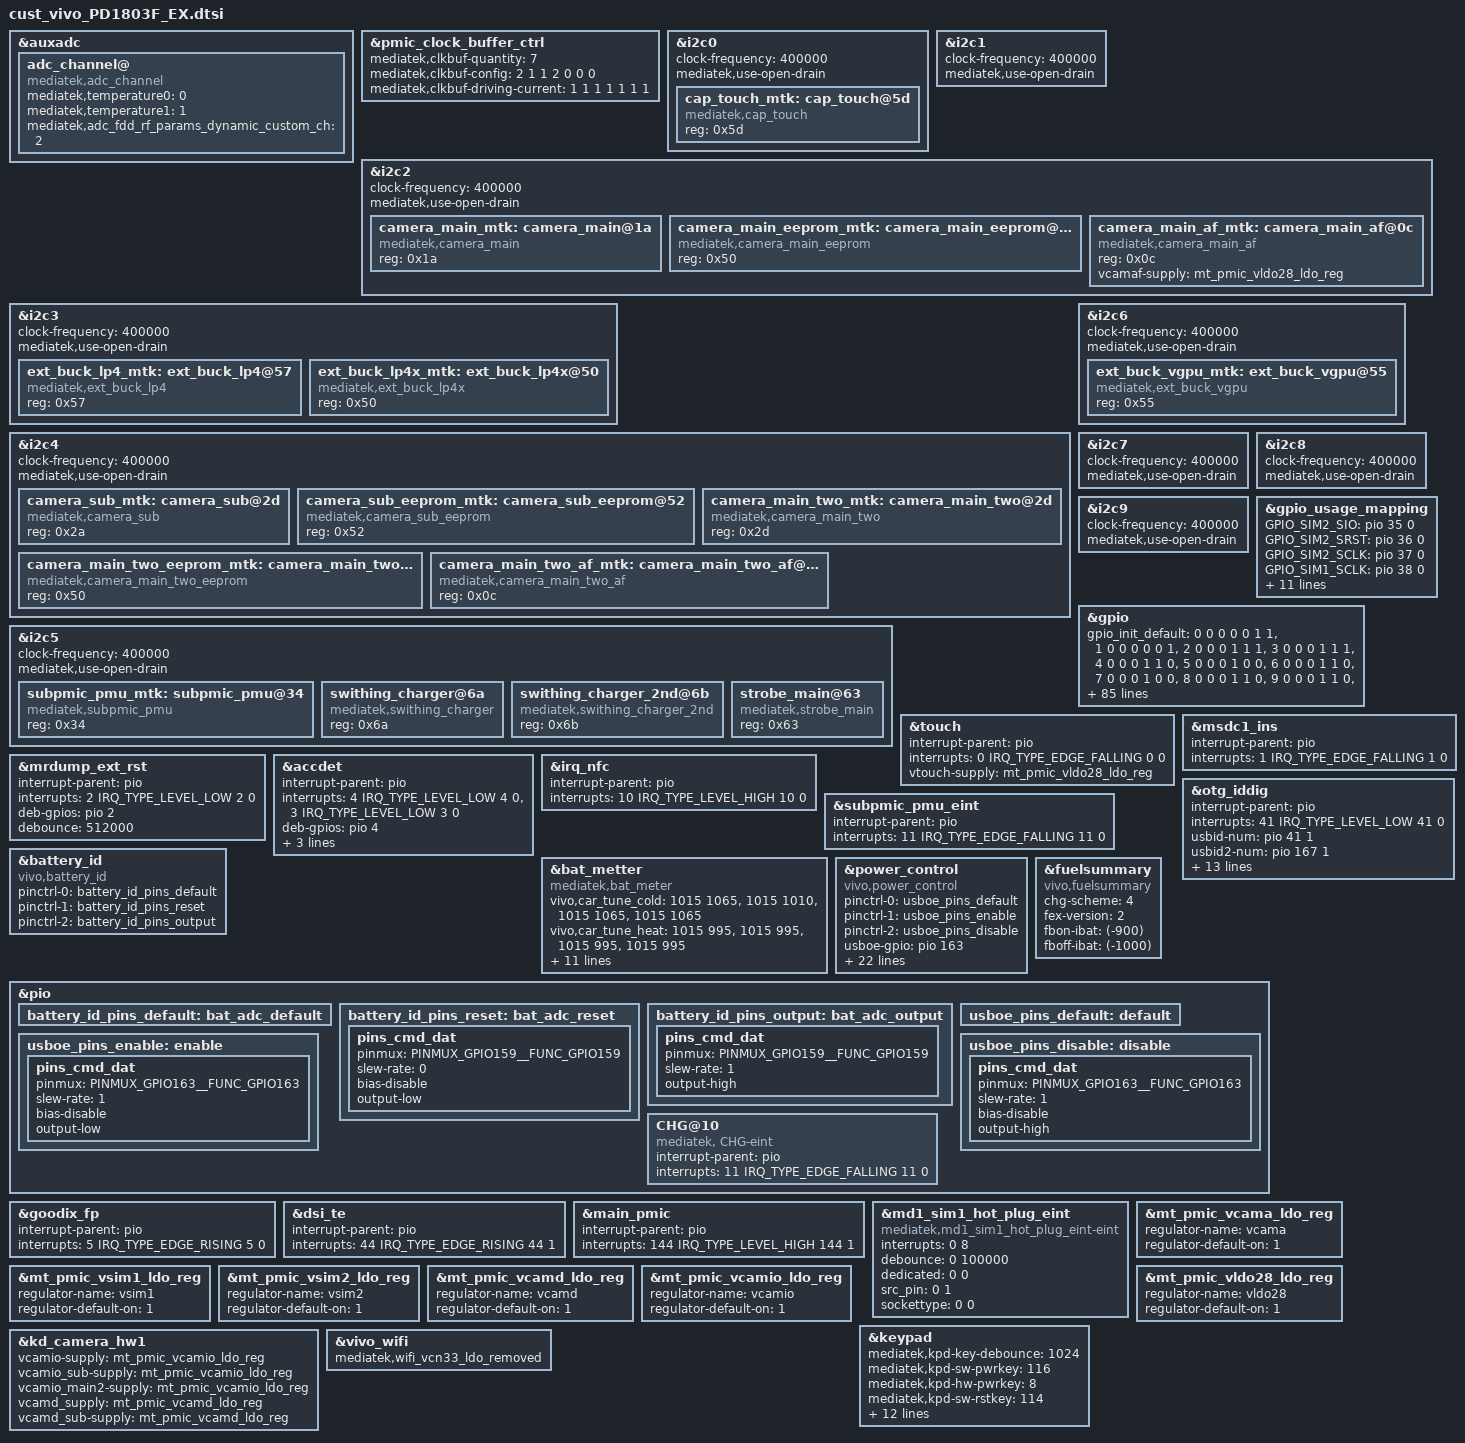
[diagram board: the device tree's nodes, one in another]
/*
 * Generated by MTK SP DrvGen Version: 3.5.160809 for MT6765.
 * 2018-01-30 14:59:45
 * Do Not Modify The File.
 * Copyright Mediatek Inc. (c) 2016.
*/

/*************************
 * ADC DTSI File
*************************/

&auxadc {
	adc_channel@ {
		compatible = "mediatek,adc_channel";
		mediatek,temperature0 = <0>;
		mediatek,temperature1 = <1>;
		mediatek,adc_fdd_rf_params_dynamic_custom_ch = <2>;
		status = "okay";
	};
};


/*************************
 * CLK_BUF DTSI File
*************************/

&pmic_clock_buffer_ctrl {
	mediatek,clkbuf-quantity = <7>;
	mediatek,clkbuf-config = <2 1 1 2 0 0 0>;
	mediatek,clkbuf-driving-current = <1 1 1 1 1 1 1>;
	status = "okay";
};


/*************************
 * I2C DTSI File
*************************/

&i2c0 {
	#address-cells = <1>;
	#size-cells = <0>;
	clock-frequency = <400000>;
	mediatek,use-open-drain;
	cap_touch_mtk:cap_touch@5d {
		compatible = "mediatek,cap_touch";
		reg = <0x5d>;
		status = "okay";
	};

};

&i2c1 {
	#address-cells = <1>;
	#size-cells = <0>;
	clock-frequency = <400000>;
	mediatek,use-open-drain;
};

&i2c2 {
	#address-cells = <1>;
	#size-cells = <0>;
	clock-frequency = <400000>;
	mediatek,use-open-drain;
	camera_main_mtk:camera_main@1a {
		compatible = "mediatek,camera_main";
		reg = <0x1a>;
		status = "okay";
	};

	camera_main_eeprom_mtk:camera_main_eeprom@50 {
		compatible = "mediatek,camera_main_eeprom";
		reg = <0x50>;
		status = "okay";
	};

	camera_main_af_mtk:camera_main_af@0c {
		compatible = "mediatek,camera_main_af";
		reg = <0x0c>;
		status = "okay";
	};

};

&i2c3 {
	#address-cells = <1>;
	#size-cells = <0>;
	clock-frequency = <400000>;
	mediatek,use-open-drain;
	ext_buck_lp4_mtk:ext_buck_lp4@57 {
		compatible = "mediatek,ext_buck_lp4";
		reg = <0x57>;
		status = "okay";
	};

	ext_buck_lp4x_mtk:ext_buck_lp4x@50 {
		compatible = "mediatek,ext_buck_lp4x";
		reg = <0x50>;
		status = "okay";
	};

};

&i2c4 {
	#address-cells = <1>;
	#size-cells = <0>;
	clock-frequency = <400000>;
	mediatek,use-open-drain;
	camera_sub_mtk:camera_sub@2d {
		compatible = "mediatek,camera_sub";
		reg = <0x2a>;
		status = "okay";
	};

	camera_sub_eeprom_mtk:camera_sub_eeprom@52 {
		compatible = "mediatek,camera_sub_eeprom";
		reg = <0x52>;
		status = "okay";
	};
	
	camera_main_two_mtk:camera_main_two@2d {
		compatible = "mediatek,camera_main_two";
		reg = <0x2d>;
		status = "okay";
	};
	
	camera_main_two_eeprom_mtk:camera_main_two_eeprom@50 {
		compatible = "mediatek,camera_main_two_eeprom";
		reg = <0x50>;
		status = "okay";
	};

	camera_main_two_af_mtk:camera_main_two_af@0c {
		compatible = "mediatek,camera_main_two_af";
		reg = <0x0c>;
		status = "okay";
	};



};

&i2c5 {
	#address-cells = <1>;
	#size-cells = <0>;
	clock-frequency = <400000>;
	mediatek,use-open-drain;
	subpmic_pmu_mtk:subpmic_pmu@34 {
		compatible = "mediatek,subpmic_pmu";
		reg = <0x34>;
		status = "okay";
	};

	swithing_charger@6a {
		compatible = "mediatek,swithing_charger";
		reg = <0x6a>;
		status = "okay";
    };
    swithing_charger_2nd@6b {
		compatible = "mediatek,swithing_charger_2nd";
		reg = <0x6b>;
		status = "okay";
    };
    	/*hope add for flashlight i2c device start*/
	strobe_main@63 {
	        compatible = "mediatek,strobe_main";
	        reg = <0x63>;
	        status = "okay";
	};
	/*hope add for flashlight i2c device end*/
};

&i2c6 {
	#address-cells = <1>;
	#size-cells = <0>;
	clock-frequency = <400000>;
	mediatek,use-open-drain;

	ext_buck_vgpu_mtk:ext_buck_vgpu@55 {
		compatible = "mediatek,ext_buck_vgpu";
		reg = <0x55>;
		status = "okay";
	};

};

&i2c7 {
	#address-cells = <1>;
	#size-cells = <0>;
	clock-frequency = <400000>;
	mediatek,use-open-drain;
};

&i2c8 {
	#address-cells = <1>;
	#size-cells = <0>;
	clock-frequency = <400000>;
	mediatek,use-open-drain;
};

&i2c9 {
	#address-cells = <1>;
	#size-cells = <0>;
	clock-frequency = <400000>;
	mediatek,use-open-drain;
};



/*************************
 * GPIO DTSI File
*************************/

&gpio_usage_mapping {
	GPIO_SIM2_SIO = <&pio 35 0>;
	GPIO_SIM2_SRST = <&pio 36 0>;
	GPIO_SIM2_SCLK = <&pio 37 0>;
	GPIO_SIM1_SCLK = <&pio 38 0>;
	GPIO_SIM1_SRST = <&pio 39 0>;
	GPIO_SIM1_SIO = <&pio 40 0>;
	GPIO_SIM1_HOT_PLUG = <&pio 47 0>;
	GPIO_FDD_BAND_SUPPORT_DETECT_1ST_PIN = <&pio 175 0>;
	GPIO_FDD_BAND_SUPPORT_DETECT_2ND_PIN = <&pio 174 0>;
	GPIO_FDD_BAND_SUPPORT_DETECT_3RD_PIN = <&pio 173 0>;
	GPIO_FDD_BAND_SUPPORT_DETECT_4TH_PIN = <&pio 176 0>;
};

&gpio{
	gpio_init_default = <0 0 0 0 0 1 1>,
		<1 0 0 0 0 0 1>,
		<2 0 0 0 1 1 1>,
		<3 0 0 0 1 1 1>,
		<4 0 0 0 1 1 0>,
		<5 0 0 0 1 0 0>,
		<6 0 0 0 1 1 0>,
		<7 0 0 0 1 0 0>,
		<8 0 0 0 1 1 0>,
		<9 0 0 0 1 1 0>,
		<10 0 0 0 0 1 0>,
		<11 0 0 0 1 1 0>,
		<12 0 0 0 1 0 0>,
		<13 3 0 0 1 0 0>,
		<14 3 1 0 0 0 0>,
		<15 3 1 0 0 0 0>,
		<16 3 1 0 0 0 0>,
		<17 0 0 0 1 0 0>,
		<18 0 0 0 1 0 0>,
		<19 0 0 0 1 0 0>,
		<20 0 0 0 1 0 0>,
		<21 0 0 0 1 0 0>,
		<22 0 0 0 1 0 0>,
		<23 0 0 0 1 0 0>,
		<24 0 0 0 1 0 0>,
		<25 0 0 0 1 0 0>,
		<26 0 0 0 1 0 0>,
		<27 0 0 0 1 0 0>,
		<28 0 0 0 1 0 0>,
		<29 1 1 0 0 0 1>,
		<30 1 0 0 1 1 1>,
		<31 1 0 0 1 1 1>,
		<32 1 0 0 1 1 1>,
		<33 1 0 0 1 1 1>,
		<34 1 0 0 1 1 1>,
		<35 1 0 0 1 1 0>,
		<36 1 1 0 0 0 0>,
		<37 1 1 0 0 0 0>,
		<38 1 1 0 0 0 0>,
		<39 1 1 0 0 0 0>,
		<40 1 0 0 1 1 0>,
		<41 0 0 0 0 0 0>,
		<42 0 0 0 1 0 0>,
		<43 1 1 0 0 0 0>,
		<44 1 0 0 1 0 0>,
		<45 0 1 0 0 0 0>,
		<46 0 0 0 0 0 0>,
		<47 1 0 0 0 0 0>,
		<48 1 0 0 0 0 0>,
		<49 1 0 0 0 0 0>,
		<50 2 0 0 1 1 0>,
		<51 2 1 0 0 0 0>,
		<52 1 1 0 1 0 0>,
		<53 1 1 0 1 0 0>,
		<54 0 0 0 1 0 0>,
		<55 0 0 0 1 0 0>,
		<56 1 1 0 1 0 0>,
		<57 0 0 0 1 0 0>,
		<58 0 0 0 1 0 0>,
		<59 1 0 0 1 0 0>,
		<60 1 0 0 1 0 0>,
		<61 1 0 0 1 0 0>,
		<62 1 0 0 1 0 0>,
		<63 1 0 0 1 0 0>,
		<64 1 0 0 1 0 0>,
		<65 1 0 0 1 0 0>,
		<66 1 0 0 1 0 0>,
		<67 1 0 0 1 0 0>,
		<68 1 0 0 1 0 0>,
		<69 1 1 0 1 0 0>,
		<70 1 1 0 1 0 0>,
		<71 0 0 0 1 0 0>,
		<72 1 1 0 1 0 0>,
		<73 0 1 0 1 0 0>,
		<74 0 1 0 1 0 0>,
		<75 0 0 0 1 0 0>,
		<76 1 1 0 1 0 0>,
		<77 1 1 0 1 0 0>,
		<78 1 1 0 1 0 0>,
		<79 0 0 0 1 0 0>,
		<80 0 0 0 1 0 0>,
		<81 1 0 0 0 0 0>,
		<82 1 0 0 0 0 0>,
		<83 1 0 0 0 0 0>,
		<84 1 0 0 0 0 0>,
		<85 1 1 0 1 0 0>,
		<86 1 1 0 1 0 0>,
		<87 0 0 0 1 0 0>,
		<88 0 0 0 1 0 0>,
		<89 0 0 0 1 0 0>,
		<90 0 0 0 1 0 0>,
		<91 0 1 0 1 0 0>,
		<92 0 0 0 1 0 0>,
		<93 1 0 0 1 1 0>,
		<94 0 0 0 1 0 0>,
		<95 1 0 0 1 1 0>,
		<96 1 1 0 0 0 0>,
		<97 0 1 0 0 0 0>,
		<98 0 1 0 0 0 0>,
		<99 1 1 0 0 0 0>,
		<100 1 1 0 0 0 0>,
		<101 0 1 1 0 0 0>,
		<102 0 1 1 0 0 0>,
		<103 1 0 0 0 0 0>,
		<104 1 0 0 0 0 0>,
		<105 1 0 0 0 0 0>,
		<106 1 0 0 0 0 0>,
		<107 0 1 0 0 0 0>,
		<108 1 1 0 0 0 0>,
		<109 0 0 0 1 1 0>,
		<110 0 0 0 1 0 0>,
		<111 0 0 0 1 0 0>,
		<112 0 0 0 1 0 0>,
		<113 0 1 0 0 0 0>,
		<114 0 0 0 1 0 0>,
		<115 0 0 0 1 0 0>,
		<116 0 0 0 1 0 0>,
		<117 0 0 0 1 0 0>,
		<118 0 0 0 1 0 0>,
		<119 0 0 0 1 0 0>,
		<120 0 0 0 1 0 0>,
		<121 0 0 0 0 0 0>,
		<122 1 0 0 1 1 1>,
		<123 1 0 0 1 1 1>,
		<124 1 1 0 0 0 1>,
		<125 1 0 0 1 1 1>,
		<126 1 0 0 1 1 1>,
		<127 1 0 0 1 1 1>,
		<128 1 0 0 1 1 1>,
		<129 1 0 0 1 1 1>,
		<130 1 0 0 1 1 1>,
		<131 1 0 0 1 0 1>,
		<132 1 0 0 1 1 1>,
		<133 1 1 1 0 0 1>,
		<134 1 0 0 1 0 0>,
		<135 1 1 0 0 0 0>,
		<136 1 1 0 0 0 0>,
		<137 1 1 0 0 0 0>,
		<138 1 1 0 0 0 0>,
		<139 1 1 0 0 0 0>,
		<140 1 0 0 1 0 0>,
		<141 1 0 0 1 0 0>,
		<142 1 0 0 1 0 0>,
		<143 1 0 0 1 0 0>,
		<144 1 0 0 1 0 0>,
		<145 1 1 1 0 0 0>,
		<146 1 0 0 1 0 0>,
		<147 1 1 0 0 0 0>,
		<148 1 1 0 0 0 0>,
		<149 1 1 0 0 0 0>,
		<150 0 1 0 1 1 0>,
		<151 0 1 0 0 0 0>,
		<152 0 1 0 0 0 0>,
		<153 0 1 0 0 0 0>,
		<154 0 1 0 0 0 0>,
		<155 0 1 0 1 0 0>,
		<156 0 0 1 0 0 0>,
		<157 1 0 0 1 0 0>,
		<158 1 0 0 1 0 0>,
		<159 0 1 1 0 0 0>,
		<160 0 0 0 1 0 0>,
		<161 1 0 0 0 0 0>,
		<162 1 0 0 0 0 0>,
		<163 0 1 0 0 0 0>,
		<164 0 0 0 0 0 0>,
		<165 0 0 0 0 0 0>,
		<166 0 1 0 1 0 0>,
		<167 0 0 0 1 0 0>,
		<168 0 0 0 1 0 0>,
		<169 0 1 0 0 0 0>,
		<170 0 1 0 0 0 0>,
		<171 0 0 0 1 1 0>,
		<172 0 0 0 1 1 0>,
		<173 0 0 0 1 1 0>,
		<174 0 0 0 1 1 0>,
		<175 0 0 0 1 1 0>,
		<176 0 0 0 1 1 0>,
		<177 0 0 0 1 1 0>,
		<178 0 1 0 0 0 0>,
		<179 0 0 0 1 0 0>;
};


/*************************
 * EINT DTSI File
*************************/

#include <dt-bindings/interrupt-controller/irq.h>
#include <dt-bindings/interrupt-controller/arm-gic.h>

&touch {
	interrupt-parent = <&pio>;
	interrupts = <0 IRQ_TYPE_EDGE_FALLING 0 0>;
	status = "okay";
};

&msdc1_ins {
	interrupt-parent = <&pio>;
	interrupts = <1 IRQ_TYPE_EDGE_FALLING 1 0>;
	status = "okay";
};

&mrdump_ext_rst {
	interrupt-parent = <&pio>;
	interrupts = <2 IRQ_TYPE_LEVEL_LOW 2 0>;
	deb-gpios = <&pio 2 0>;
	debounce = <512000>;
	status = "okay";
};

&accdet {
	interrupt-parent = <&pio>;
	interrupts = <4 IRQ_TYPE_LEVEL_LOW 4 0>,
					<3 IRQ_TYPE_LEVEL_LOW 3 0>;
	deb-gpios = <&pio 4 0>;
	deb-rgpios = <&pio 3 0>;
	debounce = <256000>;
	debounce1 = <256000>;
	status = "okay";
};

&irq_nfc {
	interrupt-parent = <&pio>;
	interrupts = <10 IRQ_TYPE_LEVEL_HIGH 10 0>;
	status = "okay";
};

&subpmic_pmu_eint {
	interrupt-parent = <&pio>;
	interrupts = <11 IRQ_TYPE_EDGE_FALLING 11 0>;
	status = "okay";
};

&otg_iddig {
    interrupt-parent = <&pio>;
    interrupts = <41 IRQ_TYPE_LEVEL_LOW 41 0>;
    /*debounce = <41 0>;*/
    usbid-num = <&pio 41 1>;
    usbid2-num = <&pio 167 1>;
    platform-id = <&pio 171 1>;
    pinctrl-names = "iddig_default", "iddig_otg_gpio", "otg_gpio_pull_high", "otg_gpio_pull_low", "otg_gpio_pull_in", "otg_gpio_pull1_high", "otg_gpio_pull1_low", "otg_gpio_pull1_in", "iddig_otg_init", "otg_gpio167_pull_high", "otg_gpio167_pull_low", "otg_gpio167_pull_in";
    pinctrl-0 = <&iddig_default>;
    pinctrl-1 = <&gpio41_mode0_gpio>;
    pinctrl-2 = <&gpio165_otg_pull_high>;
    pinctrl-3 = <&gpio165_otg_pull_low>;
    pinctrl-4 = <&gpio165_otg_pull_in>;
    pinctrl-5 = <&gpio164_otg_pull1_high>;
    pinctrl-6 = <&gpio164_otg_pull1_low>;
    pinctrl-7 = <&gpio164_otg_pull1_in>;
    pinctrl-8 = <&gpio41_mode1_iddig>;
	
    pinctrl-9 = <&gpio167_otg_pull1_high>;
    pinctrl-10 = <&gpio167_otg_pull1_low>;
    pinctrl-11 = <&gpio167_otg_pull1_in>;
    status = "okay";
};

&bat_metter {
	compatible = "mediatek,bat_meter";
	vivo,car_tune_cold = <1015 1065>,/*charging disharging for first supply*/
						 <1015 1010>,
						 <1015 1065>,
						 <1015 1065>;/*charging disharging for first supply*/
    vivo,car_tune_heat = <1015 995>,/*charging disharging for first supply*/
    					 <1015 995>,
    					 <1015 995>,
    					 <1015 995>;/*charging disharging for first supply*/
    vivo,bats-qmax = <2100 2944 3050 3114 3168>,
                     <2079 2308 2879 3110 3171>,
                     <2100 2944 3050 3114 3168>,
                     <2100 2944 3050 3114 3168>;
    vivo,bats-qmax_500ma = <2100 2884 3018 3104 3162>,
                           <3108 3071 3124 3219 3230>,
                           <2100 2884 3018 3104 3162>,
                           <2100 2884 3018 3104 3162>;
	vivo,bat-name = "B-E5 AT 3260","B-E5 SX 3260","B-E5 AT 3260","UNKOWN";
	#include "bat_setting/vivo_battery_table_pd1803f_ex.dtsi"
};

&battery_id {
    compatible = "vivo,battery_id";/*battery_id Gpio must output high from LK*/
    pinctrl-names = "bat_adc_default", "bat_adc_reset", "bat_adc_output";
    pinctrl-0 = <&battery_id_pins_default>;
    pinctrl-1 = <&battery_id_pins_reset>;
    pinctrl-2 = <&battery_id_pins_output>;
    status = "okay";
};

&power_control {
    compatible = "vivo,power_control";
    pinctrl-names = "default", "enable", "disable";
    pinctrl-0 = <&usboe_pins_default>;
    pinctrl-1 = <&usboe_pins_enable>;
    pinctrl-2 = <&usboe_pins_disable>;
    usboe-gpio = <&pio 163 0>;
    status = "okay";

    vivo,capacity-mAh = <3260>;
    vivo,large-current-timeout = <600>;
    vivo,normal-current = <2000>;
    vivo,protection-current = <2000>;
    vivo,smart-charging;
    
    vivo,tc-row-col = <8 6>;
    vivo,tc-data = <(-8888) (-1) 2000 0 0 0>,
    <0 49 2000 0 20 20>,
    <50 99 2000 0 30 30>,
    <100 149 2000 4200 70 50>,
    <150 199 2000 0 70 70>,
    <200 449 2000 4200 100 70>,
    <450 549 2000 0 50 50>,
    <550 8888 2000 0 0 0>;

    vivo,smart_fbon_tc-row-col = <6 4>;
    vivo,smart_fbon_tc-data = <(-8888) 370 2000 2048>,
    <371 400 2000 1408>,
    <401 430 2000 1216>,
    <431 480 2000 960>,
    <481 500 2000 768>,
    <501 8888 2000 512>;

    vivo,smart_fboff_tc-row-col = <5 4>;
    vivo,smart_fboff_tc-data = <(-8888) 370 2000 2048>,
    <371 390 2000 1800>,
    <391 410 2000 1600>,
    <411 450 2000 1200>,
    <451 8888 2000 512>;
};

&fuelsummary {
	compatible = "vivo,fuelsummary";

	/************************************************************
	 *
	 *  0	vivo-fastchg
	 *  1	qcom-dualchg
	 *  2	mtk-dualchg
	 *  3	qcom-normchg
	 *  4	mtk-normchg
	 *
	 ***********************************************************/
	chg-scheme = <4>;
	fex-version = <2>;
	fbon-ibat = <(-900)>;
	fboff-ibat = <(-1000)>;
};

&pio {
    battery_id_pins_default: bat_adc_default {
    };

    battery_id_pins_reset: bat_adc_reset {
        pins_cmd_dat {
            pinmux = <PINMUX_GPIO159__FUNC_GPIO159>;
            slew-rate = <0>;
            bias-disable;
            output-low;
        };
    };

    battery_id_pins_output: bat_adc_output {
        pins_cmd_dat {
            pinmux = <PINMUX_GPIO159__FUNC_GPIO159>;
            slew-rate = <1>;
            output-high;
        };
    };

    usboe_pins_default: default {
    };

    usboe_pins_enable: enable {
            pins_cmd_dat {
                pinmux = <PINMUX_GPIO163__FUNC_GPIO163>;
                slew-rate = <1>;
                bias-disable;
                output-low;
            };
       };

   usboe_pins_disable: disable {
        pins_cmd_dat {
                pinmux = <PINMUX_GPIO163__FUNC_GPIO163>;
                slew-rate = <1>;
                bias-disable;
                output-high;
        };
   };

	CHG@10 {
        compatible = "mediatek, CHG-eint";
        interrupt-parent = <&pio>;
        interrupts = <11 IRQ_TYPE_EDGE_FALLING 11 0>;
        status = "okay";
    };
   
};

&goodix_fp {
	interrupt-parent = <&pio>;
	interrupts = <5 IRQ_TYPE_EDGE_RISING 5 0>;
	status = "okay";
};

&dsi_te {
	interrupt-parent = <&pio>;
	interrupts = <44 IRQ_TYPE_EDGE_RISING 44 1>;
	status = "okay";
};

&main_pmic {
	interrupt-parent = <&pio>;
	interrupts = <144 IRQ_TYPE_LEVEL_HIGH 144 1>;
	status = "okay";
};



/*************************
 * MD1_EINT DTSI File
*************************/

&md1_sim1_hot_plug_eint {
	compatible = "mediatek,md1_sim1_hot_plug_eint-eint";
	interrupts = <0 8>;
	debounce = <0 100000>;
	dedicated = <0 0>;
	src_pin = <0 1>;
	sockettype = <0 0>;
	status = "okay";
};



/*************************
 * PMIC DTSI File
*************************/

&mt_pmic_vcama_ldo_reg {
	regulator-name = "vcama";
	regulator-default-on = <1>; /* 0:skip, 1: off, 2:on */
	status = "okay";
};
&mt_pmic_vsim1_ldo_reg {
	regulator-name = "vsim1";
	regulator-default-on = <1>; /* 0:skip, 1: off, 2:on */
	status = "okay";
};
&mt_pmic_vsim2_ldo_reg {
	regulator-name = "vsim2";
	regulator-default-on = <1>; /* 0:skip, 1: off, 2:on */
	status = "okay";
};
&mt_pmic_vcamd_ldo_reg {
	regulator-name = "vcamd";
	regulator-default-on = <1>; /* 0:skip, 1: off, 2:on */
	status = "okay";
};
&mt_pmic_vcamio_ldo_reg {
	regulator-name = "vcamio";
	regulator-default-on = <1>; /* 0:skip, 1: off, 2:on */
	status = "okay";
};
&mt_pmic_vldo28_ldo_reg {
	regulator-name = "vldo28";
	regulator-default-on = <1>; /* 0:skip, 1: off, 2:on */
	status = "okay";
};

&kd_camera_hw1 {
	/*vcama-supply = <&mt_pmic_vcama_ldo_reg>;*/
	/*vcamd_main2-supply = <&mt_pmic_vcamd_ldo_reg>;*/
	vcamio-supply = <&mt_pmic_vcamio_ldo_reg>;
	vcamio_sub-supply = <&mt_pmic_vcamio_ldo_reg>;
	vcamio_main2-supply = <&mt_pmic_vcamio_ldo_reg>;
	/*vcamaf-supply = <&mt_pmic_vldo28_ldo_reg>;*/
	vcamd_supply = <&mt_pmic_vcamd_ldo_reg>;
	vcamd_sub-supply = <&mt_pmic_vcamd_ldo_reg>;
	/*vcamaf_sub-supply = <&mt_pmic_vldo28_ldo_reg>;*/
	/*vcamaf_main2-supply = <&mt_pmic_vldo28_ldo_reg>;*/
	status = "okay";
};

/*hope add main af pmic power start*/
&camera_main_af_mtk {
	vcamaf-supply = <&mt_pmic_vldo28_ldo_reg>;
};
/*hope add main af pmic power end*/


&touch {
	vtouch-supply = <&mt_pmic_vldo28_ldo_reg>;
	status = "okay";
};


/*************************
 * POWER DTSI File
*************************/



/*************************
 * KPD DTSI File
*************************/

&keypad {
	mediatek,kpd-key-debounce = <1024>;
	mediatek,kpd-sw-pwrkey = <116>;
	mediatek,kpd-hw-pwrkey = <8>;
	mediatek,kpd-sw-rstkey  = <114>;
	mediatek,kpd-hw-rstkey = <17>;
	mediatek,kpd-use-extend-type = <0>;
	/*HW Keycode [0~71] -> Linux Keycode*/
	mediatek,kpd-hw-map-num = <72>;
	mediatek,kpd-hw-init-map = <115 114 0 0 0 0 0 0 0 0 0 0 0 0 0 0 0 0 0 0 0 0 0 0 0 0 0 0 0 0 0 0 0 0 0 0 0 0 0 0 0 0 0 0 0 0 0 0 0 0 0 0 0 0 0 0 0 0 0 0 0 0 0 0 0 0 0 0 0 0 0 0 >;
	mediatek,kpd-pwrkey-eint-gpio = <0>;
	mediatek,kpd-pwkey-gpio-din  = <0>;
	mediatek,kpd-hw-dl-key0 = <17>;
	mediatek,kpd-hw-dl-key1 = <0>;
	mediatek,kpd-hw-dl-key2 = <8>;
	mediatek,kpd-hw-recovery-key = <17>;
	mediatek,kpd-hw-factory-key = <0>;
	status = "okay";
};

/*************************
 * wifi related
*************************/
&vivo_wifi {
	mediatek,wifi_vcn33_ldo_removed;
};

